# STM8L151C6 register map
Vendor: STMicroelectronics; Series: STM8L/STM8AL, medium density; File version: 1.0
CPU: other r1p0, big endian, no MPU, no FPU, 4 interrupt priority bits
Registers are 8-bit, read-write, reset 0x0 unless marked. A register's access mark holds for its fields unless they carry their own. Offsets are from the block's base; [hi:lo] are bit positions; {n}, {i} and the like mark numbered series.

## COMP
Base 0x00005440
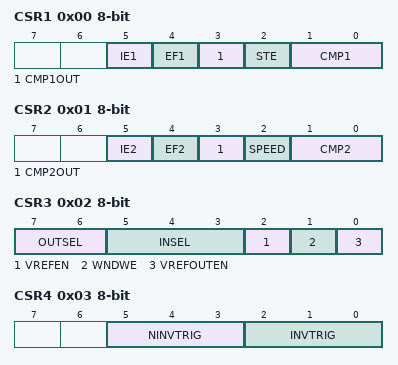
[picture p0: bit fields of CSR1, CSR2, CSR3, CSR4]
0x00 CSR1 — Comparator control and status register 1
  [5] IE1, [4] EF1, [3] CMP1OUT, [2] STE, [1:0] CMP1
0x01 CSR2 — Comparator control and status register 2
  [5] IE2, [4] EF2, [3] CMP2OUT, [2] SPEED, [1:0] CMP2
0x02 CSR3 — Comparator control and status register 3
  [7:6] OUTSEL, [5:3] INSEL, [2] VREFEN, [1] WNDWE, [0] VREFOUTEN
0x03 CSR4 — Comparator control and status register 4
  [5:3] NINVTRIG, [2:0] INVTRIG
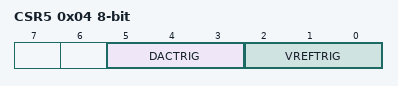
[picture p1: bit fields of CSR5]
0x04 CSR5 — Comparator control and status register 5
  [5:3] DACTRIG, [2:0] VREFTRIG

## CPU
Base 0x00007F00
0x00 A — Accumulator
0x01 PCE — Program counter extended
0x02 PCH — Program counter high
0x03 PCL — Program counter low
0x04 XH — X index register high
0x05 XL — X index register low
0x06 YH — Y index register high
0x07 YL — Y index register low
0x08 SPH reset 0x3 — Stack pointer high
0x09 SPL reset 0xFF — Stack pointer low
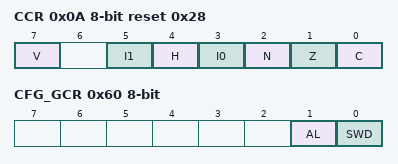
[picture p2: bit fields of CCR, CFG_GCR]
0x0A CCR reset 0x28 — Condition code register
  [7] V, [5] I1, [4] H, [3] I0, [2] N, [1] Z, [0] C
0x60 CFG_GCR — Global configuration register
  [1] AL, [0] SWD

## DAC
Base 0x00005380
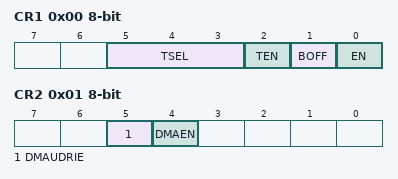
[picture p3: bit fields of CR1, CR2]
0x00 CR1 — DAC control register 1
  [5:3] TSEL, [2] TEN, [1] BOFF, [0] EN
0x01 CR2 — DAC control register 2
  [5] DMAUDRIE, [4] DMAEN
0x04 SWTRIGR — DAC software trigger register
  [0] SWTRIG
0x05 SR — DAC status register
  [0] DMAUDR
0x08 RDHRH — DAC right aligned data holding register high
  [3:0] RDHRH
0x09 RDHRL — DAC right aligned data holding register low
0x0C LDHRH — DAC left aligned data holding register high
0x0D LDHRL — DAC left aligned data holding register low
  [7:4] LDHRL
0x10 DHR8 — DAC 8-bit data holding register
0x2C DORH — DAC data output register high
  [3:0] DORH
0x2D DORL — DAC data output register low

## DM
Base 0x00007F90
0x00 BK1RE reset 0xFF — DM breakpoint 1 register extended byte
0x01 BK1RH reset 0xFF — DM breakpoint 1 register high byte
0x02 BK1RL reset 0xFF — DM breakpoint 1 register low byte
0x03 BK2RE reset 0xFF — DM breakpoint 2 register extended byte
0x04 BK2RH reset 0xFF — DM breakpoint 2 register high byte
0x05 BK2RL reset 0xFF — DM breakpoint 2 register low byte
0x06 CR1 — DM Debug module control register 1
0x07 CR2 — DM Debug module control register 2
0x08 CSR1 reset 0x10 — DM Debug module control/status register 1
0x09 CSR2 — DM Debug module control/status register 2
0x0A ENFCTR reset 0xFF — DM enable function register

## DMA1
Base 0x00005070
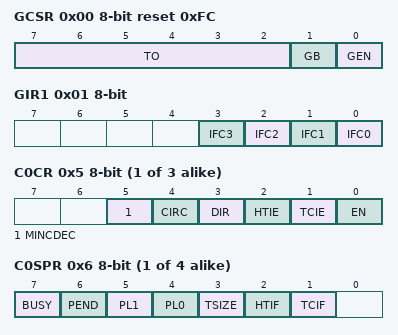
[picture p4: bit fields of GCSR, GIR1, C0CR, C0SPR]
0x00 GCSR reset 0xFC — DMA1 global configuration & status register
  [7:2] TO, [1] GB, [0] GEN
0x01 GIR1 — DMA1 global interrupt register 1
  [n] IFC{n} (n=0..3)
{0x5+0xA*i} C{i}CR (i=0..2) — DMA1 channel {i} configuration register
  [5] MINCDEC, [4] CIRC, [3] DIR, [2] HTIE, [1] TCIE, [0] EN
{0x6+0xA*i} C{i}SPR (i=0..3) — DMA1 channel {i} status
  [7] BUSY, [6] PEND, [5] PL1, [4] PL0, [3] TSIZE, [2] HTIF, [1] TCIF
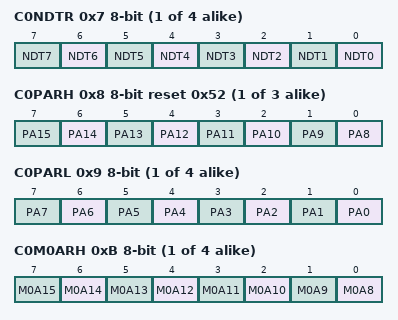
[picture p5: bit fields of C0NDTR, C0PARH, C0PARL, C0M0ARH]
{0x7+0xA*i} C{i}NDTR (i=0..3) — DMA1 number of data to transfer register (channel {i})
  [n] NDT{n} (n=0..7)
{0x8+0xA*i} C{i}PARH reset 0x52 (i=0..2) — DMA1 peripheral address high register (channel {i})
  [n-8] PA{n} (n=8..15)
{0x9+0xA*i} C{i}PARL (i=0..3) — DMA1 peripheral address low register (channel {i})
  [n] PA{n} (n=0..7)
{0xB+0xA*i} C{i}M0ARH (i=0..3) — DMA1 memory 0 address high register (channel {i})
  [n-8] M0A{n} (n=8..15)
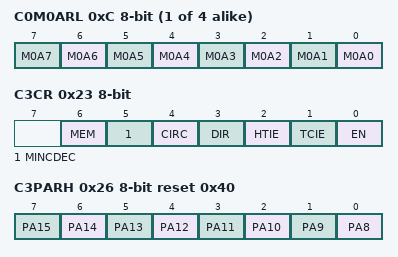
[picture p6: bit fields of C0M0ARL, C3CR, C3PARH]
{0xC+0xA*i} C{i}M0ARL (i=0..3) — DMA1 memory 0 address low register (channel {i})
  [n] M0A{n} (n=0..7)
0x23 C3CR — DMA1 channel 3 configuration register
  [6] MEM, [5] MINCDEC, [4] CIRC, [3] DIR, [2] HTIE, [1] TCIE, [0] EN
0x26 C3PARH reset 0x40 — DMA1 peripheral address high register (channel 3)
  [n-8] PA{n} (n=8..15)
